# STM32H7RSxx register map
File version: 0.1
CPU: CM7 r0p1, little endian, MPU, FPU, 4 interrupt priority bits
Registers are 32-bit, read-write, reset 0x0 unless marked. A register's access mark holds for its fields unless they carry their own. Offsets are from the block's base; [hi:lo] are bit positions; lines under a group give offsets from that group; {n}, {i} and the like mark numbered series; 'fields as' and 'values as' point back to an identical list.

## ADC1 (part 2 of 2) — Analog to digital converter
Base 0x40022000
Same registers: ADC2 0x40022100
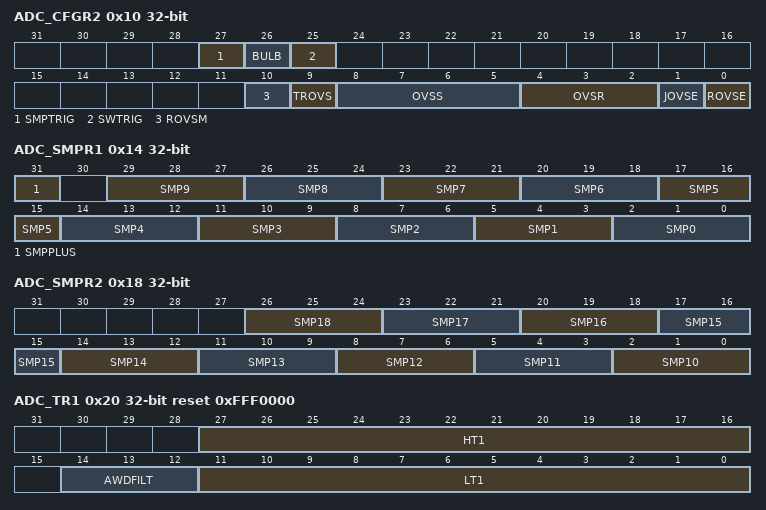
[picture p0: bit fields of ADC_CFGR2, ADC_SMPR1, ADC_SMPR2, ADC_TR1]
0x10 ADC_CFGR2 — ADC configuration register 2
  [27] SMPTRIG — Sampling time control trigger mode This bit is set and cleared by software to enable the sampling time control trigger mode. The sampling time starts on the trigger rising edge, and the conversion on the trigger falling edge. EXTEN bit should be set to 01. BULB bit must not be set when the SMPTRIG bit is set. When EXTEN bit is set to 00, set SWTRIG to start the sampling and clear SWTRIG bit to start the conversion. Note: The software is allowed to write this bit only when ADSTART = 0 (which ensures that no conversion is ongoing).
    0=Sampling time control trigger mode disabled; 1=Sampling time control trigger mode enabled
  [26] BULB — Bulb sampling mode This bit is set and cleared by software to enable the bulb sampling mode. SAMPTRIG bit must not be set when the BULB bit is set. The very first ADC conversion is performed with the sampling time specified in SMPx bits. Note: The software is allowed to write this bit only when ADSTART = 0 (which ensures that no conversion is ongoing).
    0=Bulb sampling mode disabled; 1=Bulb sampling mode enabled. The sampling period starts just after the previous end of conversion.
  [25] SWTRIG — Software trigger bit for sampling time control trigger mode This bit is set and cleared by software to enable the bulb sampling mode. Note: The software is allowed to write this bit only when ADSTART = 0 (which ensures that no conversion is ongoing).
    0=Software trigger starts the conversion for sampling time control trigger mode; 1=Software trigger starts the sampling for sampling time control trigger mode
  [10] ROVSM — Regular Oversampling mode This bit is set and cleared by software to select the regular oversampling mode. Note: The software is allowed to write this bit only when ADSTART = 0 (which ensures that no conversion is ongoing).
    0=Continued mode: When injected conversions are triggered, the oversampling is temporary stopped and continued after the injection sequence (oversampling buffer is maintained during injected sequence); 1=Resumed mode: When injected conversions are triggered, the current oversampling is aborted and resumed from start after the injection sequence (oversampling buffer is zeroed by injected sequence start)
  [9] TROVS — Triggered Regular Oversampling This bit is set and cleared by software to enable triggered oversampling Note: The software is allowed to write this bit only when ADSTART = 0 (which ensures that no conversion is ongoing).
    0=All oversampled conversions for a channel are done consecutively following a trigger; 1=Each oversampled conversion for a channel needs a new trigger
  [8:5] OVSS — Oversampling shift This bitfield is set and cleared by software to define the right shifting applied to the raw oversampling result. Other codes reserved Note: The software is allowed to write these bits only when ADSTART = 0 (which ensures that no conversion is ongoing).
    0=No shift; 1=Shift 1-bit; {v}=Shift {v}-bits (v=2..8)
  [4:2] OVSR — Oversampling ratio This bitfield is set and cleared by software to define the oversampling ratio. Note: The software is allowed to write these bits only when ADSTART = 0 (which ensures that no conversion is ongoing).
    0=2x; 1=4x; 2=8x; 3=16x; 4=32x; 5=64x; 6=128x; 7=256x
  [1] JOVSE — Injected Oversampling Enable This bit is set and cleared by software to enable injected oversampling. Note: The software is allowed to write this bit only when ADSTART = 0 and JADSTART = 0 (which ensures that no conversion is ongoing)
    0=Injected Oversampling disabled; 1=Injected Oversampling enabled
  [0] ROVSE — Regular Oversampling Enable This bit is set and cleared by software to enable regular oversampling. Note: The software is allowed to write this bit only when ADSTART = 0 and JADSTART = 0 (which ensures that no conversion is ongoing)
    0=Regular Oversampling disabled; 1=Regular Oversampling enabled
0x14 ADC_SMPR1 — ADC sample time register 1
  [31] SMPPLUS — Addition of one clock cycle to the sampling time. To make sure no conversion is ongoing, the software is allowed to write this bit only when ADSTART = 0 and JADSTART = 0.
    1=2.5 ADC clock cycle sampling time becomes 3.5 ADC clock cycles for the ADC_SMPR1 and ADC_SMPR2 registers; 0=The sampling time remains set to 2.5 ADC clock cycles remains
  [3n+2:3n] SMP{n} (n=0..9) — Channel x sampling time selection These bits are written by software to select the sampling time individually for each channel. During sample cycles, the channel selection bits must remain unchanged. Note: The software is allowed to write these bits only when ADSTART = 0 and JADSTART = 0 (which ensures that no conversion is ongoing). Some channels are not connected physically. Keep the corresponding SMPx[2:0] setting to the reset value.
    0=2.5 ADC clock cycles; 1=6.5 ADC clock cycles; 2=12.5 ADC clock cycles; 3=24.5 ADC clock cycles; 4=47.5 ADC clock cycles; 5=92.5 ADC clock cycles; 6=247.5 ADC clock cycles; 7=640.5 ADC clock cycles
0x18 ADC_SMPR2 — ADC sample time register 2
  [all] fields
    values as ADC_SMPR1.SMP0
  [3n-28:3n-30] SMP{n} (n=10..18) — Channel x sampling time selection These bits are written by software to select the sampling time individually for each channel. During sampling cycles, the channel selection bits must remain unchanged. Note: The software is allowed to write these bits only when ADSTART = 0 and JADSTART = 0 (which ensures that no conversion is ongoing). Some channels are not connected physically. Keep the corresponding SMPx[2:0] setting to the reset value.
0x20 ADC_TR1 reset 0xFFF0000 — ADC watchdog threshold register 1
  [27:16] HT1 — Analog watchdog 1 higher threshold These bits are written by software to define the higher threshold for the analog watchdog 1. Refer to AWD2CH, AWD3CH, AWD_HTx, AWD_LTx, AWDx) Note: The software is allowed to write these bits only when ADSTART = 0 and JADSTART = 0 (which ensures that no conversion is ongoing).
  [14:12] AWDFILT — Analog watchdog filtering parameter This bit is set and cleared by software. ... Note: The software is allowed to write this bit only when ADSTART = 0 (which ensures that no conversion is ongoing).
    0=No filtering; 1=two consecutive detection generates an AWDx flag or an interrupt; 7=Eight consecutive detection generates an AWDx flag or an interrupt
  [11:0] LT1 — Analog watchdog 1 lower threshold These bits are written by software to define the lower threshold for the analog watchdog 1. Refer to AWD2CH, AWD3CH, AWD_HTx, AWD_LTx, AWDx) Note: The software is allowed to write these bits only when ADSTART = 0 and JADSTART = 0 (which ensures that no conversion is ongoing).
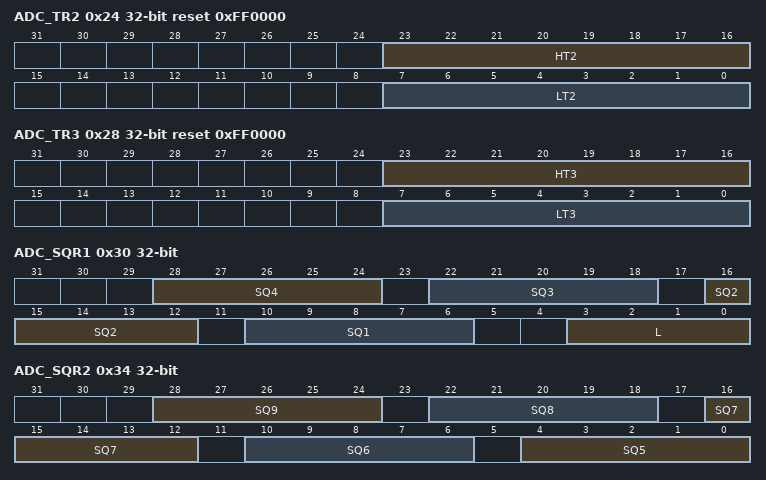
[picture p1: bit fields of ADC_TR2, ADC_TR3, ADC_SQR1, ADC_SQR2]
0x24 ADC_TR2 reset 0xFF0000 — ADC watchdog threshold register 2
  [23:16] HT2 — Analog watchdog 2 higher threshold These bits are written by software to define the higher threshold for the analog watchdog 2. Refer to AWD2CH, AWD3CH, AWD_HTx, AWD_LTx, AWDx) Note: The software is allowed to write these bits only when ADSTART = 0 and JADSTART = 0 (which ensures that no conversion is ongoing).
  [7:0] LT2 — Analog watchdog 2 lower threshold These bits are written by software to define the lower threshold for the analog watchdog 2. Refer to AWD2CH, AWD3CH, AWD_HTx, AWD_LTx, AWDx) Note: The software is allowed to write these bits only when ADSTART = 0 and JADSTART = 0 (which ensures that no conversion is ongoing).
0x28 ADC_TR3 reset 0xFF0000 — ADC watchdog threshold register 3
  [23:16] HT3 — Analog watchdog 3 higher threshold These bits are written by software to define the higher threshold for the analog watchdog 3. Refer to AWD2CH, AWD3CH, AWD_HTx, AWD_LTx, AWDx) Note: The software is allowed to write these bits only when ADSTART = 0 and JADSTART = 0 (which ensures that no conversion is ongoing).
  [7:0] LT3 — Analog watchdog 3 lower threshold These bits are written by software to define the lower threshold for the analog watchdog 3. This watchdog compares the 8-bit of LT3 with the 8 MSB of the converted data. Note: The software is allowed to write these bits only when ADSTART = 0 and JADSTART = 0 (which ensures that no conversion is ongoing).
0x30 ADC_SQR1 — ADC regular sequence register 1
  [28:24] SQ4 — 4th conversion in regular sequence These bits are written by software with the channel number (0 to 19) assigned as the 4th in the regular conversion sequence. Note: The software is allowed to write these bits only when ADSTART = 0 (which ensures that no regular conversion is ongoing).
  [22:18] SQ3 — 3rd conversion in regular sequence These bits are written by software with the channel number (0 to 19) assigned as the 3rd in the regular conversion sequence. Note: The software is allowed to write these bits only when ADSTART = 0 (which ensures that no regular conversion is ongoing).
  [16:12] SQ2 — 2nd conversion in regular sequence These bits are written by software with the channel number (0 to 19) assigned as the 2nd in the regular conversion sequence. Note: The software is allowed to write these bits only when ADSTART = 0 (which ensures that no regular conversion is ongoing).
  [10:6] SQ1 — 1st conversion in regular sequence These bits are written by software with the channel number (0 to 19) assigned as the 1st in the regular conversion sequence. Note: The software is allowed to write these bits only when ADSTART = 0 (which ensures that no regular conversion is ongoing).
  [3:0] L — Regular channel sequence length These bits are written by software to define the total number of conversions in the regular channel conversion sequence. ... Note: The software is allowed to write these bits only when ADSTART = 0 (which ensures that no regular conversion is ongoing).
    0=1 conversion; 1=2 conversions; 15=16 conversions
0x34 ADC_SQR2 — ADC regular sequence register 2
  [28:24] SQ9 — 9th conversion in regular sequence These bits are written by software with the channel number (0 to 19) assigned as the 9th in the regular conversion sequence. Note: The software is allowed to write these bits only when ADSTART = 0 (which ensures that no regular conversion is ongoing).
  [22:18] SQ8 — 8th conversion in regular sequence These bits are written by software with the channel number (0 to 19) assigned as the 8th in the regular conversion sequence Note: The software is allowed to write these bits only when ADSTART = 0 (which ensures that no regular conversion is ongoing).
  [16:12] SQ7 — 7th conversion in regular sequence These bits are written by software with the channel number (0 to 19) assigned as the 7th in the regular conversion sequence. Note: The software is allowed to write these bits only when ADSTART = 0 (which ensures that no regular conversion is ongoing).
  [10:6] SQ6 — 6th conversion in regular sequence These bits are written by software with the channel number (0 to 19) assigned as the 6th in the regular conversion sequence. Note: The software is allowed to write these bits only when ADSTART = 0 (which ensures that no regular conversion is ongoing).
  [4:0] SQ5 — 5th conversion in regular sequence These bits are written by software with the channel number (0 to 19) assigned as the 5th in the regular conversion sequence. Note: The software is allowed to write these bits only when ADSTART = 0 (which ensures that no regular conversion is ongoing).
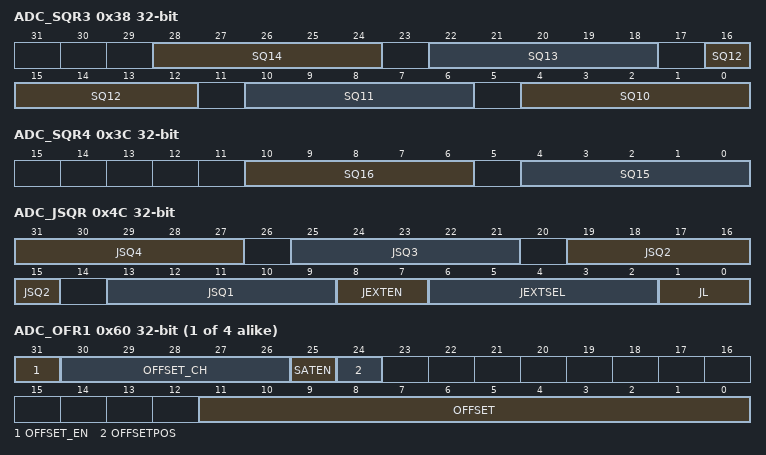
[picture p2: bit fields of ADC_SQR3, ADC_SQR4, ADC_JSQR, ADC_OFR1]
0x38 ADC_SQR3 — ADC regular sequence register 3
  [6n-56:6n-60] SQ{n} (n=10..14) — {n}th conversion in regular sequence These bits are written by software with the channel number (0 to 19) assigned as the {n}th in the regular conversion sequence. Note: The software is allowed to write these bits only when ADSTART = 0 (which ensures that no regular conversion is ongoing).
0x3C ADC_SQR4 — ADC regular sequence register 4
  [10:6] SQ16 — 16th conversion in regular sequence These bits are written by software with the channel number (0 to 19) assigned as the 16th in the regular conversion sequence. Note: The software is allowed to write these bits only when ADSTART = 0 (which ensures that no regular conversion is ongoing).
  [4:0] SQ15 — 15th conversion in regular sequence These bits are written by software with the channel number (0 to 19) assigned as the 15th in the regular conversion sequence. Note: The software is allowed to write these bits only when ADSTART = 0 (which ensures that no regular conversion is ongoing).
0x40 ADC_DR ro — ADC regular data register
  [15:0] RDATA — Regular data converted These bits are read-only. They contain the conversion result from the last converted regular channel. The data are left- or right-aligned as described in .
0x4C ADC_JSQR — ADC injected sequence register
  [31:27] JSQ4 — 4th conversion in the injected sequence These bits are written by software with the channel number (0 to 19) assigned as the 4th in the injected conversion sequence. Note: The software is allowed to write these bits only when JADSTART = 0 (which ensures that no injected conversion is ongoing).
  [25:21] JSQ3 — 3rd conversion in the injected sequence These bits are written by software with the channel number (0 to 19) assigned as the 3rd in the injected conversion sequence. Note: The software is allowed to write these bits only when JADSTART = 0 (which ensures that no injected conversion is ongoing).
  [19:15] JSQ2 — 2nd conversion in the injected sequence These bits are written by software with the channel number (0 to 19) assigned as the 2nd in the injected conversion sequence. Note: The software is allowed to write these bits only when JADSTART = 0 (which ensures that no injected conversion is ongoing).
  [13:9] JSQ1 — 1st conversion in the injected sequence These bits are written by software with the channel number (0 to 19) assigned as the 1st in the injected conversion sequence. Note: The software is allowed to write these bits only when JADSTART = 0 (which ensures that no injected conversion is ongoing).
  [8:7] JEXTEN — External trigger enable and polarity selection for injected channels These bits are set and cleared by software to select the external trigger polarity and enable the trigger of an injected group. Note: The software is allowed to write these bits only when JADSTART = 0 (which ensures that no injected conversion is ongoing). If JQM = 1 and if the Queue of Context becomes empty, the software and hardware triggers of the injected sequence are both internally disabled (refer to Queue of context for injected conversions)
    0=If JQDIS = 0 (queue enabled), hardware and software trigger detection disabled. Otherwise, the queue is disabled as well as hardware trigger detection (conversions can be launched by software); 1=Hardware trigger detection on the rising edge; 2=Hardware trigger detection on the falling edge; 3=Hardware trigger detection on both the rising and falling edges
  [6:2] JEXTSEL — External Trigger Selection for injected group These bits select the external event used to trigger the start of conversion of an injected group: ... Note: The software is allowed to write these bits only when JADSTART = 0 (which ensures that no injected conversion is ongoing).
    {v}=adc_jext_trg{v} (v=0..7); 31=adc_jext_trg31
  [1:0] JL — Injected channel sequence length These bits are written by software to define the total number of conversions in the injected channel conversion sequence. Note: The software is allowed to write these bits only when JADSTART = 0 (which ensures that no injected conversion is ongoing).
    0=1 conversion; 1=2 conversions; 2=3 conversions; 3=4 conversions
{0x5C+4i} ADC_OFR{i} (i=1..4) — ADC offset {i} register
  [31] OFFSET_EN — Offset y enable This bit is written by software to enable or disable the offset programmed into bits OFFSET[11:0]. Note: The software is allowed to write this bit only when ADSTART = 0 and JADSTART = 0 (which ensures that no conversion is ongoing).
  [30:26] OFFSET_CH — Channel selection for the data offset y These bits are written by software to define the channel to which the offset programmed into bits OFFSET[11:0] applies. Note: The software is allowed to write these bits only when ADSTART = 0 and JADSTART = 0 (which ensures that no conversion is ongoing). Some channels are not connected physically and must not be selected for the data offset y. If OFFSET_EN is set, it is not allowed to select the same channel for different ADC_OFRy registers.
  [25] SATEN — Saturation enable This bit is set and cleared by software to enable the saturation at 0x000 and 0xFFF for the offset function. Note: The software is allowed to write these bits only when ADSTART = 0 and JADSTART = 0 (which ensures that no conversion is ongoing).
    0=No saturation control, offset result can be signed; 1=Saturation enabled, offset result unsigned and saturated at 0x000 and 0xFFF
  [24] OFFSETPOS — Positive offset This bit is set and cleared by software to enable the positive offset. Note: The software is allowed to write these bits only when ADSTART = 0 and JADSTART = 0 (which ensures that no conversion is ongoing).
    0=Negative offset; 1=Positive offset
  [11:0] OFFSET — Data offset y for the channel programmed into bits OFFSET_CH[4:0] These bits are written by software to define the offset to be subtracted from the raw converted data when converting a channel (can be regular or injected). The channel to which applies the data offset must be programmed in the bits OFFSET_CH[4:0]. The conversion result can be read from in the ADC_DR (regular conversion) or from in the ADC_JDRyi registers (injected conversion). Note: The software is allowed to write these bits only when ADSTART = 0 and JADSTART = 0 (which ensures that no conversion is ongoing). If several offset (OFFSET) point to the same channel, only the offset with the lowest x value is considered for the subtraction. Ex: if OFFSET1_CH[4:0] = 4 and OFFSET2_CH[4:0] = 4, this is OFFSET1[11:0] which is subtracted when converting channel 4.
{0x7C+4i} ADC_JDR{i} ro (i=1..4) — ADC injected channel {i} data register
  [15:0] JDATA — Injected data These bits are read-only. They contain the conversion result from injected channel y. The data are left -or right-aligned as described in .
0xA0 ADC_AWD2CR — ADC Analog Watchdog 2 Configuration Register
  [18:0] AWD2CH — Analog watchdog 2 channel selection These bits are set and cleared by software. They enable and select the input channels to be guarded by the analog watchdog 2. AWD2CH[i] = 0: ADC analog input channel i is not monitored by AWD2 AWD2CH[i] = 1: ADC analog input channel i is monitored by AWD2 When AWD2CH[18:0] = 000..0, the analog Watchdog 2 is disabled Note: The channels selected by AWD2CH must be also selected into the SQRi or JSQRi registers. The software is allowed to write these bits only when ADSTART = 0 and JADSTART = 0 (which ensures that no conversion is ongoing). Some channels are not connected physically and must not be selected for the analog watchdog.
0xA4 ADC_AWD3CR — ADC Analog Watchdog 3 Configuration Register
  [18:0] AWD3CH — Analog watchdog 3 channel selection These bits are set and cleared by software. They enable and select the input channels to be guarded by the analog watchdog 3. AWD3CH[i] = 0: ADC analog input channel i is not monitored by AWD3 AWD3CH[i] = 1: ADC analog input channel i is monitored by AWD3 When AWD3CH[18:0] = 000..0, the analog Watchdog 3 is disabled Note: The channels selected by AWD3CH must be also selected into the SQRi or JSQRi registers. The software is allowed to write these bits only when ADSTART = 0 and JADSTART = 0 (which ensures that no conversion is ongoing). Some channels are not connected physically and must not be selected for the analog watchdog.
0xB0 ADC_DIFSEL — ADC Differential mode Selection Register
  [18:0] DIFSEL — Differential mode for channels 18 to 0. These bits are set and cleared by software. They allow to select if a channel is configured as Single-ended or Differential mode. DIFSEL[i] = 0: ADC analog input channel is configured in Single-ended mode DIFSEL[i] = 1: ADC analog input channel i is configured in Differential mode Note: The DIFSEL bits corresponding to channels that are either connected to a single-ended I/O port or to an internal channel must be kept their reset value (Single-ended input mode). The software is allowed to write these bits only when the ADC is disabled (ADCAL = 0, JADSTART = 0, JADSTP = 0, ADSTART = 0, ADSTP = 0, ADDIS = 0 and ADEN = 0).
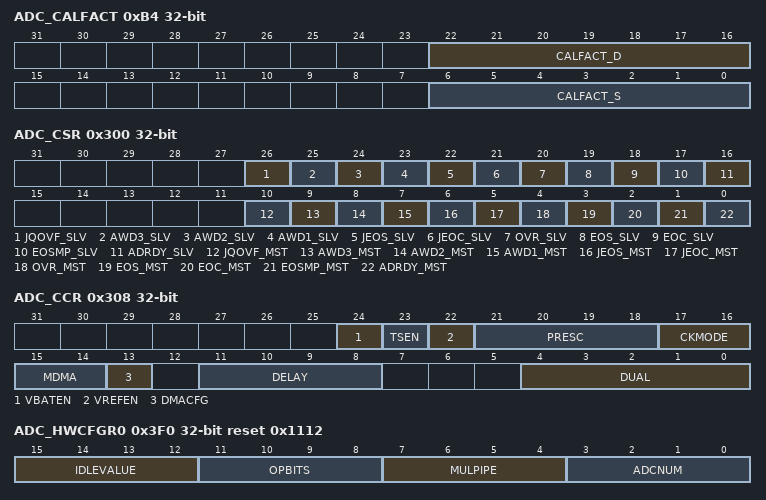
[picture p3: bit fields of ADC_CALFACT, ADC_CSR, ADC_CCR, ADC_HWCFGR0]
0xB4 ADC_CALFACT — ADC Calibration Factors
  [22:16] CALFACT_D — Calibration Factors in differential mode These bits are written by hardware or by software. Once a differential inputs calibration is complete, they are updated by hardware with the calibration factors. Software can write these bits with a new calibration factor. If the new calibration factor is different from the current one stored into the analog ADC, it is then applied once a new differential calibration is launched. Note: The software is allowed to write these bits only when ADEN = 1, ADSTART = 0 and JADSTART = 0 (ADC is enabled and no calibration is ongoing and no conversion is ongoing).
  [6:0] CALFACT_S — Calibration Factors In Single-ended mode These bits are written by hardware or by software. Once a single-ended inputs calibration is complete, they are updated by hardware with the calibration factors. Software can write these bits with a new calibration factor. If the new calibration factor is different from the current one stored into the analog ADC, it is then applied once a new single-ended calibration is launched. Note: The software is allowed to write these bits only when ADEN = 1, ADSTART = 0 and JADSTART = 0 (ADC is enabled and no calibration is ongoing and no conversion is ongoing).
0xC8 ADC_OR — ADC option register
  [0] OP0 — VDDCORE channel enable
    0=VDDCORE channel disabled; 1=VDDCORE channel enabled
0x300 ADC_CSR ro — ADC common status register
  [26] JQOVF_SLV — Injected Context Queue Overflow flag of the slave ADC This bit is a copy of the JQOVF bit in the corresponding ADC_ISR register.
  [25] AWD3_SLV — Analog watchdog 3 flag of the slave ADC This bit is a copy of the AWD3 bit in the corresponding ADC_ISR register.
  [24] AWD2_SLV — Analog watchdog 2 flag of the slave ADC This bit is a copy of the AWD2 bit in the corresponding ADC_ISR register.
  [23] AWD1_SLV — Analog watchdog 1 flag of the slave ADC This bit is a copy of the AWD1 bit in the corresponding ADC_ISR register.
  [22] JEOS_SLV — End of injected sequence flag of the slave ADC This bit is a copy of the JEOS bit in the corresponding ADC_ISR register.
  [21] JEOC_SLV — End of injected conversion flag of the slave ADC This bit is a copy of the JEOC bit in the corresponding ADC_ISR register.
  [20] OVR_SLV — Overrun flag of the slave ADC This bit is a copy of the OVR bit in the corresponding ADC_ISR register.
  [19] EOS_SLV — End of regular sequence flag of the slave ADC. This bit is a copy of the EOS bit in the corresponding ADC_ISR register.
  [18] EOC_SLV — End of regular conversion of the slave ADC This bit is a copy of the EOC bit in the corresponding ADC_ISR register.
  [17] EOSMP_SLV — End of Sampling phase flag of the slave ADC This bit is a copy of the EOSMP2 bit in the corresponding ADC_ISR register.
  [16] ADRDY_SLV — Slave ADC ready This bit is a copy of the ADRDY bit in the corresponding ADC_ISR register.
  [10] JQOVF_MST — Injected Context Queue Overflow flag of the master ADC This bit is a copy of the JQOVF bit in the corresponding ADC_ISR register.
  [9] AWD3_MST — Analog watchdog 3 flag of the master ADC This bit is a copy of the AWD3 bit in the corresponding ADC_ISR register.
  [8] AWD2_MST — Analog watchdog 2 flag of the master ADC This bit is a copy of the AWD2 bit in the corresponding ADC_ISR register.
  [7] AWD1_MST — Analog watchdog 1 flag of the master ADC This bit is a copy of the AWD1 bit in the corresponding ADC_ISR register.
  [6] JEOS_MST — End of injected sequence flag of the master ADC This bit is a copy of the JEOS bit in the corresponding ADC_ISR register.
  [5] JEOC_MST — End of injected conversion flag of the master ADC This bit is a copy of the JEOC bit in the corresponding ADC_ISR register.
  [4] OVR_MST — Overrun flag of the master ADC This bit is a copy of the OVR bit in the corresponding ADC_ISR register.
  [3] EOS_MST — End of regular sequence flag of the master ADC This bit is a copy of the EOS bit in the corresponding ADC_ISR register.
  [2] EOC_MST — End of regular conversion of the master ADC This bit is a copy of the EOC bit in the corresponding ADC_ISR register.
  [1] EOSMP_MST — End of Sampling phase flag of the master ADC This bit is a copy of the EOSMP bit in the corresponding ADC_ISR register.
  [0] ADRDY_MST — Master ADC ready This bit is a copy of the ADRDY bit in the corresponding ADC_ISR register.
0x308 ADC_CCR — ADC common control register
  [24] VBATEN — VBAT enable This bit is set and cleared by software to control.
    0=VBAT channel disabled; 1=VBAT channel enabled
  [23] TSEN — VSENSE enable This bit is set and cleared by software to control VSENSE.
    0=Temperature sensor channel disabled; 1=Temperature sensor channel enabled
  [22] VREFEN — VREFINT enable This bit is set and cleared by software to enable/disable the VREFINT channel.
    0=VREFINT channel disabled; 1=VREFINT channel enabled
  [21:18] PRESC — ADC prescaler These bits are set and cleared by software to select the frequency of the clock to the ADC. The clock is common for all the ADCs. other: reserved Note: The software is allowed to write these bits only when the ADC is disabled (ADCAL = 0, JADSTART = 0, ADSTART = 0, ADSTP = 0, ADDIS = 0 and ADEN = 0). The ADC prescaler value is applied only when CKMODE[1:0] = 0b00.
    0=input ADC clock not divided; 1=input ADC clock divided by 2; 2=input ADC clock divided by 4; 3=input ADC clock divided by 6; 4=input ADC clock divided by 8; 5=input ADC clock divided by 10; 6=input ADC clock divided by 12; 7=input ADC clock divided by 16; 8=input ADC clock divided by 32; 9=input ADC clock divided by 64; 10=input ADC clock divided by 128; 11=input ADC clock divided by 256
  [17:16] CKMODE — ADC clock mode These bits are set and cleared by software to define the ADC clock scheme (which is common to both master and slave ADCs): In all synchronous clock modes, there is no jitter in the delay from a timer trigger to the start of a conversion. Note: The software is allowed to write these bits only when the ADCs are disabled (ADCAL = 0, JADSTART = 0, ADSTART = 0, ADSTP = 0, ADDIS = 0 and ADEN = 0).
    0=adc_ker_ck (x = 1/2) (Asynchronous clock mode), generated at product level (refer to Section 6: Reset and clock control (RCC)); 1=adc_hclk/1 (Synchronous clock mode). This configuration must be enabled only if the AHB clock prescaler is set to 1 (HPRE[3:0] = 0XXX in RCC_CFGR register) and if the system clock has a 50% duty cycle.; 2=adc_hclk/2 (Synchronous clock mode); 3=adc_hclk/4 (Synchronous clock mode)
  [15:14] MDMA — Direct memory access mode for dual ADC mode This bitfield is set and cleared by software. Refer to the DMA controller section for more details. Note: The software is allowed to write these bits only when ADSTART = 0 (which ensures that no regular conversion is ongoing).
    0=MDMA mode disabled; 2=MDMA mode enabled for 12 and 10-bit resolution; 3=MDMA mode enabled for 8 and 6-bit resolution
  [13] DMACFG — DMA configuration (for dual ADC mode) This bit is set and cleared by software to select between two DMA modes of operation and is effective only when DMAEN = 1. For more details, refer to Note: The software is allowed to write these bits only when ADSTART = 0 (which ensures that no regular conversion is ongoing).
    0=DMA One Shot mode selected; 1=DMA Circular mode selected
  [11:8] DELAY — Delay between 2 sampling phases These bits are set and cleared by software. These bits are used in dual interleaved modes. Refer to for the value of ADC resolution versus DELAY bits values. Note: The software is allowed to write these bits only when the ADCs are disabled (ADCAL = 0, JADSTART = 0, ADSTART = 0, ADSTP = 0, ADDIS = 0 and ADEN = 0).
  [4:0] DUAL — Dual ADC mode selection These bits are written by software to select the operating mode. 0 value means Independent Mode. Values 00001 to 01001 means Dual mode, master and slave ADCs are working together. All other combinations are reserved and must not be programmed Note: The software is allowed to write these bits only when the ADCs are disabled (ADCAL = 0, JADSTART = 0, ADSTART = 0, ADSTP = 0, ADDIS = 0 and ADEN = 0).
    0=Independent mode; 1=Combined regular simultaneous + injected simultaneous mode; 2=Combined regular simultaneous + alternate trigger mode; 3=Combined Interleaved mode + injected simultaneous mode; 5=Injected simultaneous mode only; 6=Regular simultaneous mode only; 7=Interleaved mode only; 9=Alternate trigger mode only
0x3F0 ADC_HWCFGR0 ro reset 0x1112 — ADC hardware configuration register
  [15:12] IDLEVALUE — Idle value for non-selected channels
    0=Dummy channel selection is 0x13; 1=Dummy channel selection is 0x1F
  [11:8] OPBITS — Number of option bits
    0=No option register implemented; 1=1 option bit implemented in the ADC option register (ADC_OR) at address offset 0xC8
  [7:4] MULPIPE — Number of pipeline stages
    1=One-stage pipeline
  [3:0] ADCNUM — Number of ADCs implemented
    1=One ADC instance implemented; 2=Two ADC instances implemented; 3=Three ADCs instances implemented
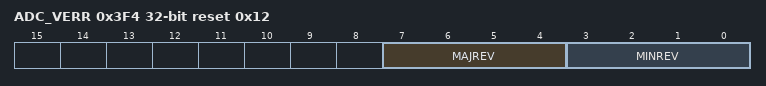
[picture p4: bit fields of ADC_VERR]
0x3F4 ADC_VERR ro reset 0x12 — ADC version register
  [7:4] MAJREV — Major revision These bits returns the ADC IP major revision
    1=Major revision = 1.X
  [3:0] MINREV — Minor revision These bits returns the ADC IP minor revision 0002: Major revision = X.2
    1=Major revision = X.1
0x3F8 ADC_IPDR ro reset 0x110006 — ADC identification register
  [31:0] ID — Peripheral identifier These bits returns the ADC identifier. ID[31:0] = 0x0011 0006: c7amba_aditf5_90_v1
0x3FC ADC_SIDR ro reset 0xA3C5DD01 — ADC size identification register
  [31:0] SID — Size Identification SID[31:8]: fixed code that characterizes the ADC_SIDR register. This field is always read at 0xA3C5DD. SID[7:0]: read-only numeric field that returns the address offset (in Kbytes) of the identification registers from the IP base address:
    1=1 Kbytes address offset; 2=2 Kbytes address offset; 4=4 Kbytes address offset; 8=8 Kbytes address offset
